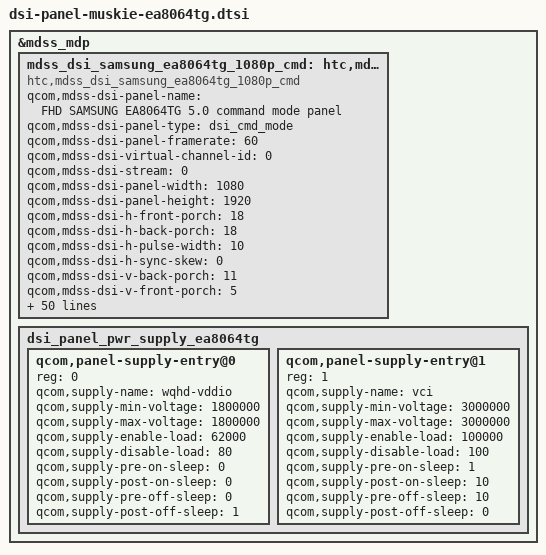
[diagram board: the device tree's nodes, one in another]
/* Copyright (c) 2016, The Linux Foundation. All rights reserved.
 *
 * This program is free software; you can redistribute it and/or modify
 * it under the terms of the GNU General Public License version 2 and
 * only version 2 as published by the Free Software Foundation.
 *
 * This program is distributed in the hope that it will be useful,
 * but WITHOUT ANY WARRANTY; without even the implied warranty of
 * MERCHANTABILITY or FITNESS FOR A PARTICULAR PURPOSE.  See the
 * GNU General Public License for more details.
 */
&mdss_mdp {
	mdss_dsi_samsung_ea8064tg_1080p_cmd: htc,mdss_dsi_samsung_ea8064tg_1080p_cmd {
		compatible = "htc,mdss_dsi_samsung_ea8064tg_1080p_cmd";
		qcom,mdss-dsi-panel-name = "FHD SAMSUNG EA8064TG 5.0 command mode panel";
		qcom,mdss-dsi-panel-type = "dsi_cmd_mode";
		qcom,mdss-dsi-panel-framerate = <60>;
		qcom,mdss-dsi-virtual-channel-id = <0>;
		qcom,mdss-dsi-stream = <0>;
		qcom,mdss-dsi-panel-width = <1080>;
		qcom,mdss-dsi-panel-height = <1920>;
		qcom,mdss-dsi-h-front-porch = <18>;
		qcom,mdss-dsi-h-back-porch = <18>;
		qcom,mdss-dsi-h-pulse-width = <10>;
		qcom,mdss-dsi-h-sync-skew = <0>;
		qcom,mdss-dsi-v-back-porch = <11>;
		qcom,mdss-dsi-v-front-porch = <5>;
		qcom,mdss-dsi-v-pulse-width = <2>;
		qcom,mdss-dsi-h-left-border = <0>;
		qcom,mdss-dsi-h-right-border = <0>;
		qcom,mdss-dsi-v-top-border = <0>;
		qcom,mdss-dsi-v-bottom-border = <0>;
		qcom,mdss-pan-physical-width-dimension  = <62>;
		qcom,mdss-pan-physical-height-dimension = <110>;
		qcom,mdss-dsi-bpp = <24>;
		qcom,mdss-dsi-color-order = "rgb_swap_rgb";
		qcom,mdss-dsi-underflow-color = <0xff>;
		qcom,mdss-dsi-border-color = <0>;
		qcom,mdss-dsi-h-sync-pulse = <0>;
		qcom,mdss-dsi-traffic-mode = "non_burst_sync_event";
		qcom,mdss-dsi-lane-map = "lane_map_0123";
		qcom,mdss-dsi-bllp-eof-power-mode;
		qcom,mdss-dsi-bllp-power-mode;
		qcom,mdss-dsi-panel-broadcast-mode;
		qcom,mdss-dsi-lane-0-state;
		qcom,mdss-dsi-lane-1-state;
		qcom,mdss-dsi-lane-2-state;
		qcom,mdss-dsi-lane-3-state;
		qcom,mdss-dsi-panel-timings = [00 1A 05 05 09 0E 06 06 04 03 04 00];
		qcom,mdss-dsi-t-clk-post = <0x07>;
		qcom,mdss-dsi-t-clk-pre = <0x26>;
		qcom,mdss-dsi-reset-sequence =  <1 2>, <0 1>, <1 10>;
		qcom,mdss-dsi-bl-pmic-control-type = "bl_ctrl_dcs";
		qcom,mdss-dsi-bl-min-level = <1>;
		qcom,mdss-dsi-bl-max-level = <255>;
		qcom,mdss-dsi-dma-trigger = "trigger_sw";
		qcom,mdss-dsi-mdp-trigger = "none";
		qcom,mdss-dsi-wr-mem-start = <0x2c>;
		qcom,mdss-dsi-wr-mem-continue = <0x3c>;
		qcom,mdss-dsi-te-pin-select = <1>;
		qcom,mdss-dsi-te-dcs-command = <1>;
		qcom,mdss-dsi-te-check-enable;
		qcom,mdss-dsi-te-using-te-pin;
		qcom,dcs-cmd-by-left;
		qcom,mdss-dsi-on-command = [
			05 01 00 00 14 00 02 11 00 /* sleep out */
			05 01 00 00 00 00 02 35 00 /* TE on */
			29 01 00 00 00 00 03 FC 5A 5A /* key unlock */
			29 01 00 00 00 00 03 F4 00 01 /* clk setting */
			29 01 00 00 00 00 03 FC A5 A5 /* key lock */
			15 01 00 00 00 00 02 53 20 /* brightness control (dimming) */
			05 01 00 00 00 00 02 29 00 /* display on */
		];
		qcom,mdss-dsi-on-command-state = "dsi_lp_mode";
		qcom,mdss-dsi-off-command = [
			05 01 00 00 23 00 02 28 00
			05 01 00 00 96 00 02 10 00
		];
		qcom,mdss-dsi-off-command-state = "dsi_hs_mode";
		/* qcom,mdss-dsi-default-command-state = "dsi_hs_mode"; */
		qcom,cont-splash-enabled;
		qcom,mdss-dsi-lp11-init;
		qcom,panel-supply-entries = <&dsi_panel_pwr_supply_ea8064tg>;
		/*qcom,mdss-dsi-panel-status-check-mode = "te_signal_check";*/
	};
	dsi_panel_pwr_supply_ea8064tg: dsi_panel_pwr_supply_ea8064tg {
		#address-cells = <1>;
		#size-cells = <0>;
		qcom,panel-supply-entry@0 {
			reg = <0>;
			qcom,supply-name = "wqhd-vddio";
			qcom,supply-min-voltage = <1800000>;
			qcom,supply-max-voltage = <1800000>;
			qcom,supply-enable-load = <62000>;
			qcom,supply-disable-load = <80>;
			qcom,supply-pre-on-sleep = <0>;
			qcom,supply-post-on-sleep = <0>;
			qcom,supply-pre-off-sleep = <0>;
			qcom,supply-post-off-sleep = <1>;
		};
		qcom,panel-supply-entry@1 {
			reg = <1>;
			qcom,supply-name = "vci";
			qcom,supply-min-voltage = <3000000>;
			qcom,supply-max-voltage = <3000000>;
			qcom,supply-enable-load = <100000>;
			qcom,supply-disable-load = <100>;
			qcom,supply-pre-on-sleep = <1>;
			qcom,supply-post-on-sleep = <10>;
			qcom,supply-pre-off-sleep = <10>;
			qcom,supply-post-off-sleep = <0>;
		 };
	};
};
